# LM3S2432 register map
File version: 7944
Registers are 32-bit, read-write, no defined reset value unless marked. A register's access mark holds for its fields unless they carry their own. Offsets are from the block's base; [hi:lo] are bit positions; {n}, {i} and the like mark numbered series.

## COMP — Register map for COMP peripheral
Base 0x4003C000; register names take the prefix COMP
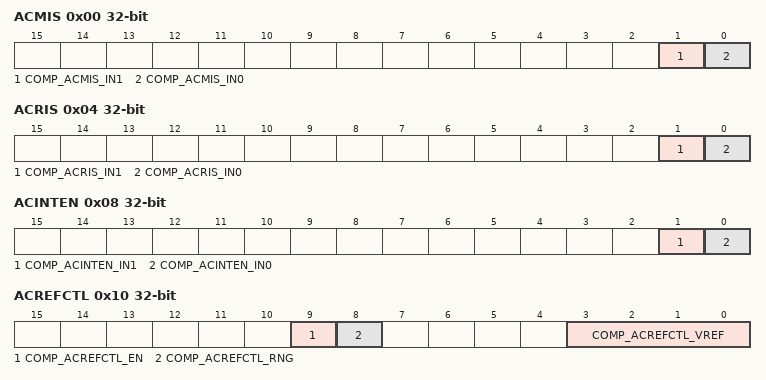
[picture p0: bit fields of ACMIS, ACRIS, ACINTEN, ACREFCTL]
0x00 ACMIS — Analog Comparator Masked Interrupt Status
  [1] COMP_ACMIS_IN1 — Comparator 1 Masked Interrupt Status
  [0] COMP_ACMIS_IN0 — Comparator 0 Masked Interrupt Status
0x04 ACRIS — Analog Comparator Raw Interrupt Status
  [1] COMP_ACRIS_IN1 — Comparator 1 Interrupt Status
  [0] COMP_ACRIS_IN0 — Comparator 0 Interrupt Status
0x08 ACINTEN — Analog Comparator Interrupt Enable
  [1] COMP_ACINTEN_IN1 — Comparator 1 Interrupt Enable
  [0] COMP_ACINTEN_IN0 — Comparator 0 Interrupt Enable
0x10 ACREFCTL — Analog Comparator Reference Voltage Control
  [9] COMP_ACREFCTL_EN — Resistor Ladder Enable
  [8] COMP_ACREFCTL_RNG — Resistor Ladder Range
  [3:0] COMP_ACREFCTL_VREF — Resistor Ladder Voltage Ref
0x20 ACSTAT0 — Analog Comparator Status 0
  [1] COMP_ACSTAT0_OVAL — Comparator Output Value
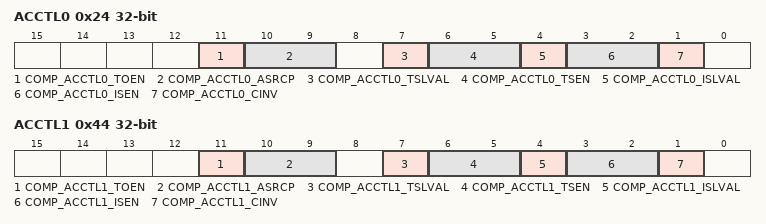
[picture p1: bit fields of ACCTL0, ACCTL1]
0x24 ACCTL0 — Analog Comparator Control 0
  [11] COMP_ACCTL0_TOEN — Trigger Output Enable
  [10:9] COMP_ACCTL0_ASRCP — Analog Source Positive
    0=COMP_ACCTL0_ASRCP_PIN (Pin value of Cn+); 1=COMP_ACCTL0_ASRCP_PIN0 (Pin value of C0+); 2=COMP_ACCTL0_ASRCP_REF (Internal voltage reference (VIREF))
  [7] COMP_ACCTL0_TSLVAL — Trigger Sense Level Value
  [6:5] COMP_ACCTL0_TSEN — Trigger Sense
    0=COMP_ACCTL0_TSEN_LEVEL (Level sense, see TSLVAL); 1=COMP_ACCTL0_TSEN_FALL (Falling edge); 2=COMP_ACCTL0_TSEN_RISE (Rising edge); 3=COMP_ACCTL0_TSEN_BOTH (Either edge)
  [4] COMP_ACCTL0_ISLVAL — Interrupt Sense Level Value
  [3:2] COMP_ACCTL0_ISEN — Interrupt Sense
    0=COMP_ACCTL0_ISEN_LEVEL (Level sense, see ISLVAL); 1=COMP_ACCTL0_ISEN_FALL (Falling edge); 2=COMP_ACCTL0_ISEN_RISE (Rising edge); 3=COMP_ACCTL0_ISEN_BOTH (Either edge)
  [1] COMP_ACCTL0_CINV — Comparator Output Invert
0x40 ACSTAT1 — Analog Comparator Status 1
  [1] COMP_ACSTAT1_OVAL — Comparator Output Value
0x44 ACCTL1 — Analog Comparator Control 1
  [11] COMP_ACCTL1_TOEN — Trigger Output Enable
  [10:9] COMP_ACCTL1_ASRCP — Analog Source Positive
    0=COMP_ACCTL1_ASRCP_PIN (Pin value of Cn+); 1=COMP_ACCTL1_ASRCP_PIN0 (Pin value of C0+); 2=COMP_ACCTL1_ASRCP_REF (Internal voltage reference (VIREF))
  [7] COMP_ACCTL1_TSLVAL — Trigger Sense Level Value
  [6:5] COMP_ACCTL1_TSEN — Trigger Sense
    0=COMP_ACCTL1_TSEN_LEVEL (Level sense, see TSLVAL); 1=COMP_ACCTL1_TSEN_FALL (Falling edge); 2=COMP_ACCTL1_TSEN_RISE (Rising edge); 3=COMP_ACCTL1_TSEN_BOTH (Either edge)
  [4] COMP_ACCTL1_ISLVAL — Interrupt Sense Level Value
  [3:2] COMP_ACCTL1_ISEN — Interrupt Sense
    0=COMP_ACCTL1_ISEN_LEVEL (Level sense, see ISLVAL); 1=COMP_ACCTL1_ISEN_FALL (Falling edge); 2=COMP_ACCTL1_ISEN_RISE (Rising edge); 3=COMP_ACCTL1_ISEN_BOTH (Either edge)
  [1] COMP_ACCTL1_CINV — Comparator Output Invert

## FLASH_CTRL — Register map for FLASH_CTRL peripheral
Base 0x400FD000; register names take the prefix FLASH_CTRL
0x00 FMA — Flash Memory Address
  [16:0] FLASH_FMA_OFFSET — Address Offset
0x04 FMD — Flash Memory Data
  [31:0] FLASH_FMD_DATA — Data Value
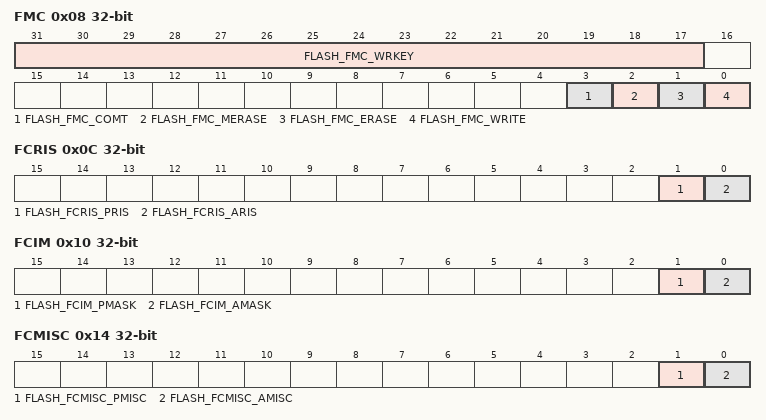
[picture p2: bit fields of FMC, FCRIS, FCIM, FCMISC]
0x08 FMC — Flash Memory Control
  [31:17] FLASH_FMC_WRKEY — FLASH write key
  [3] FLASH_FMC_COMT — Commit Register Value
  [2] FLASH_FMC_MERASE — Mass Erase Flash Memory
  [1] FLASH_FMC_ERASE — Erase a Page of Flash Memory
  [0] FLASH_FMC_WRITE — Write a Word into Flash Memory
0x0C FCRIS — Flash Controller Raw Interrupt Status
  [1] FLASH_FCRIS_PRIS — Programming Raw Interrupt Status
  [0] FLASH_FCRIS_ARIS — Access Raw Interrupt Status
0x10 FCIM — Flash Controller Interrupt Mask
  [1] FLASH_FCIM_PMASK — Programming Interrupt Mask
  [0] FLASH_FCIM_AMASK — Access Interrupt Mask
0x14 FCMISC — Flash Controller Masked Interrupt Status and Clear
  [1] FLASH_FCMISC_PMISC — Programming Masked Interrupt Status and Clear
  [0] FLASH_FCMISC_AMISC — Access Masked Interrupt Status and Clear
0x1140 USECRL — USec Reload
  [7:0] FLASH_USECRL — Microsecond Reload Value
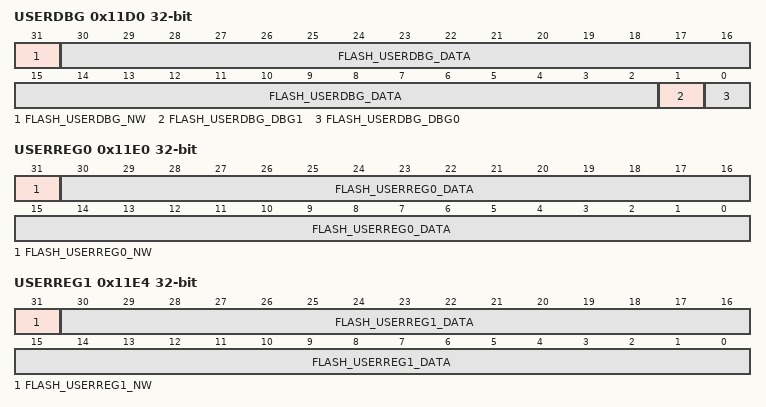
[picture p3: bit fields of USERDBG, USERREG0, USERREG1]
0x11D0 USERDBG (FLASH_ALT view) — User Debug
  [31] FLASH_USERDBG_NW — User Debug Not Written
  [30:2] FLASH_USERDBG_DATA — User Data
  [1] FLASH_USERDBG_DBG1 — Debug Control 1
  [0] FLASH_USERDBG_DBG0 — Debug Control 0
0x11E0 USERREG0 — User Register 0
  [31] FLASH_USERREG0_NW — Not Written
  [30:0] FLASH_USERREG0_DATA — User Data
0x11E4 USERREG1 — User Register 1
  [31] FLASH_USERREG1_NW — Not Written
  [30:0] FLASH_USERREG1_DATA — User Data
{0x1200+4i} FMPRE{i} (i=0..3) — Flash Memory Protection Read Enable {i}
{0x1400+4i} FMPPE{i} (i=0..3) — Flash Memory Protection Program Enable {i}
